# STM32WBA50xx register map
File version: 1.0
Registers are 32-bit, read-write, reset 0x0 unless marked. A register's access mark holds for its fields unless they carry their own. Offsets are from the block's base; [hi:lo] are bit positions; {n}, {i} and the like mark numbered series; 'fields as' and 'values as' point back to an identical list.

## PKA
Base 0x420C2000
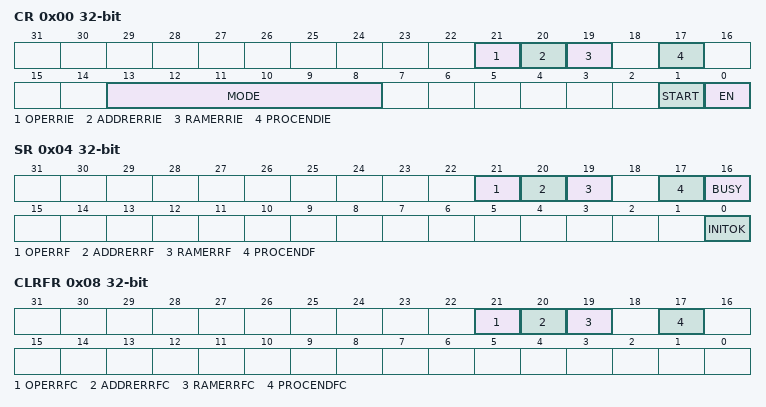
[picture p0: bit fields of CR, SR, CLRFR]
0x00 CR — PKA control register
  [21] OPERRIE — Operation Error interrupt enable
  [20] ADDRERRIE — Address error interrupt enable
  [19] RAMERRIE — RAM error interrupt enable
  [17] PROCENDIE — End of operation interrupt enable
  [13:8] MODE — MODE[5:0] PKA operation code
  [1] START — Start operation
  [0] EN — PKA enable
0x04 SR — PKA status register
  [21] OPERRF — PKA operation Error flag
  [20] ADDRERRF — Address error flag
  [19] RAMERRF — PKA RAM error flag
  [17] PROCENDF — PKA end of operation flag
  [16] BUSY — PKA operation is in progress
  [0] INITOK — PKA initialisation flag
0x08 CLRFR — PKA clear flag register
  [21] OPERRFC — Clear PKA operation Error flag
  [20] ADDRERRFC — Clear address error flag
  [19] RAMERRFC — Clear PKA RAM error flag
  [17] PROCENDFC — Clear PKA end of operation flag
{0x400+4i} RAM[{i}] (i=0..1333)

## SYSCFG — System configuration controller
Base 0x46000400
0x00 SECCFGR — SYSCFG secure configuration register
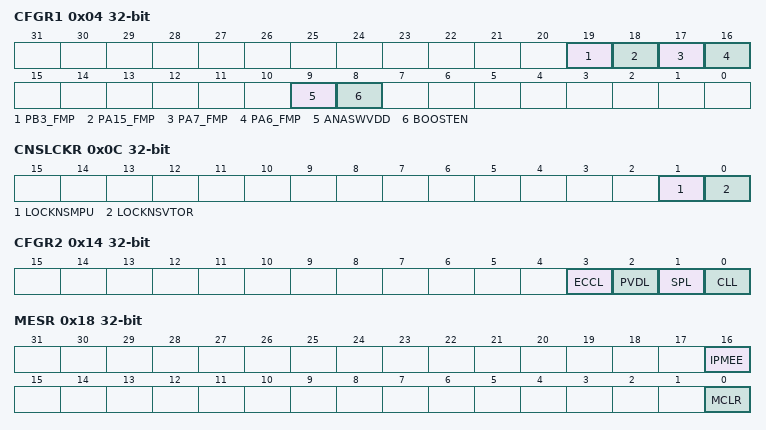
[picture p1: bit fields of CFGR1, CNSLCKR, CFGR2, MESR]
0x04 CFGR1 — SYSCFG configuration register 1
  [19] PB3_FMP — I2C PB3 Fast mode plus
  [18] PA15_FMP — I2C PA15 Fast mode plus
  [17] PA7_FMP — I2C PA7 Fast mode plus
  [16] PA6_FMP — I2C PA6 Fast mode plus
  [9] ANASWVDD — GPIO analog switch control voltage selection
  [8] BOOSTEN — I/O analog switch voltage booster enable
0x08 FPUIMR — SYSCFG FPU interrupt mask register
  [5:0] FPU_IE — All FPU interrupts enable
0x0C CNSLCKR — SYSCFG CPU non-secure lock register
  [1] LOCKNSMPU — Disable Non-Secure MPU registers writes by SW or debug agent
  [0] LOCKNSVTOR — Disable VTOR_NS register writes by SW or debug agent
0x10 CSLCKR — SYSCFG CPU secure lock register
0x14 CFGR2 — SYSCFG configuration register 2
  [3] ECCL — ECC Lock
  [2] PVDL — PVD Lock
  [1] SPL — SRAM Parity Lock
  [0] CLL — Core Lockup Lock
0x18 MESR — SYSCFG Memory Erase Status register
  [16] IPMEE — Status of End of Erase for ICache and PKA RAMs
  [0] MCLR — Status of Erase after Reset
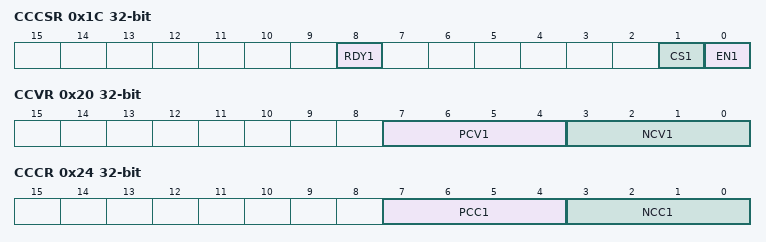
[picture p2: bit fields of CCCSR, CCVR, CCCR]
0x1C CCCSR — SYSCFG Conpensation Cell Control&Status register
  [8] RDY1 — VDD compensation cell ready flag
  [1] CS1 — Code selection for VDD power rail
  [0] EN1 — Enable compensation cell for VDD power rail
0x20 CCVR — SYSCFG Conpensation Cell value register
  [7:4] PCV1 — PMOS compensation value for VDD Power Rail
  [3:0] NCV1 — NMOS compensation value for VDD Power Rail
0x24 CCCR — SYSCFG Conpensation Cell Code register
  [7:4] PCC1 — PMOS compensation code for VDD Power Rail
  [3:0] NCC1 — NMOS compensation code for VDD Power Rail
0x2C RSSCMDR — SYSCFG RSS command mode register

## RTC — Real-Time Clock
Base 0x46007800
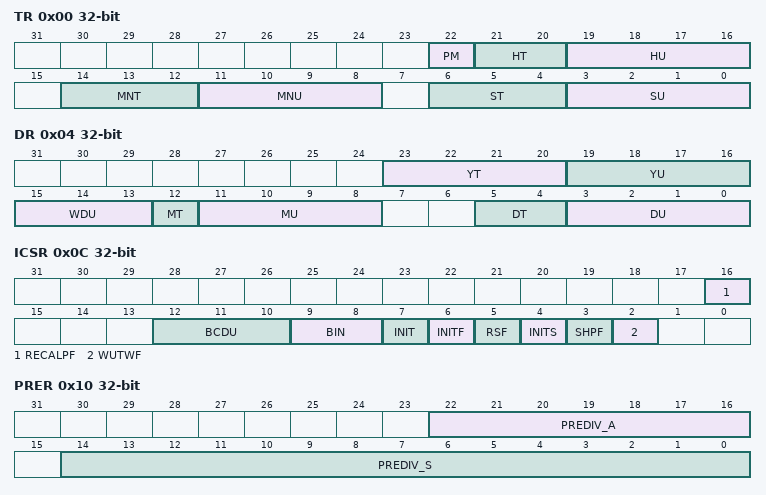
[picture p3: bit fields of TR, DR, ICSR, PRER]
0x00 TR — RTC time register
  [22] PM
    0=AM_OR_24 (AM or 24-hour format); 1=PM
  [21:20] HT
  [19:16] HU
  [14:12] MNT
  [11:8] MNU
  [6:4] ST
  [3:0] SU
0x04 DR — RTC date register
  [23:20] YT, [19:16] YU, [15:13] WDU, [12] MT, [11:8] MU, [5:4] DT, [3:0] DU
0x08 SSR — RTC sub second register
  [31:0] SS
0x0C ICSR — RTC initialization control and status register
  [16] RECALPF
  [12:10] BCDU
    {v}=1s calendar increment is generated each time SS[{v+7}:0] = 0 (v=0..7)
  [9:8] BIN
    0=NONE (Free running BCD calendar mode (Binary mode disabled)); 1=ONLY (Free running Binary mode (BCD mode disabled)); 2=MIX (Free running BCD calendar and Binary mode enable)
  [7] INIT
  [6] INITF
  [5] RSF
  [4] INITS
  [3] SHPF
  [2] WUTWF
0x10 PRER — RTC prescaler register
  [22:16] PREDIV_A, [14:0] PREDIV_S
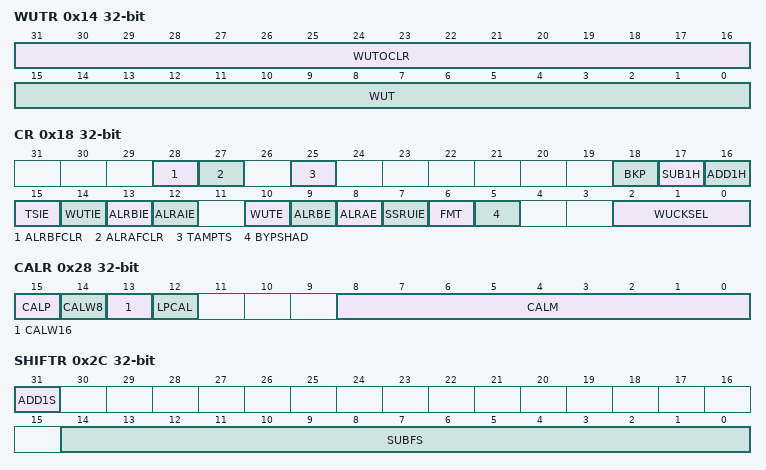
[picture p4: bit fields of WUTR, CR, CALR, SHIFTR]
0x14 WUTR — RTC wakeup timer register
  [31:16] WUTOCLR, [15:0] WUT
0x18 CR — RTC control register
  [28] ALRBFCLR — Alarm B mask
  [27] ALRAFCLR — Alarm A mask
  [25] TAMPTS — Activate timestamp on tamper detection event
  [18] BKP
  [17] SUB1H
  [16] ADD1H
  [15] TSIE
  [14] WUTIE
  [13] ALRBIE
  [12] ALRAIE
  [10] WUTE
  [9] ALRBE
  [8] ALRAE
  [7] SSRUIE
  [6] FMT
    0=HOURFORMAT_24HOUR (24 hour/day format); 1=AMPM (AM/PM hour format)
  [5] BYPSHAD
  [2:0] WUCKSEL
    0=DIV_16 (RTC/16 clock is selected); 1=DIV_8 (RTC/8 clock is selected); 2=DIV_4 (RTC/4 clock is selected); 3=DIV_2 (RTC/2 clock is selected); 4=CKSPRE (ck_spre (usually 1 Hz) clock is selected); 6=CKSPRE_WUT (ck_spre (usually 1 Hz) clock is selected and 2exp16 is added to the WUT counter value)
0x24 WPR — RTC write protection register
  [7:0] KEY
0x28 CALR — RTC calibration register
  [15] CALP
    0=NONE (No RTCCLK pulses are added); 1=SET (One RTCCLK pulse is effectively inserted every 2exp11 pulses (frequency increased by 488.5 ppm))
  [14] CALW8
  [13] CALW16
  [12] LPCAL
  [8:0] CALM
0x2C SHIFTR — RTC shift control register
  [31] ADD1S, [14:0] SUBFS
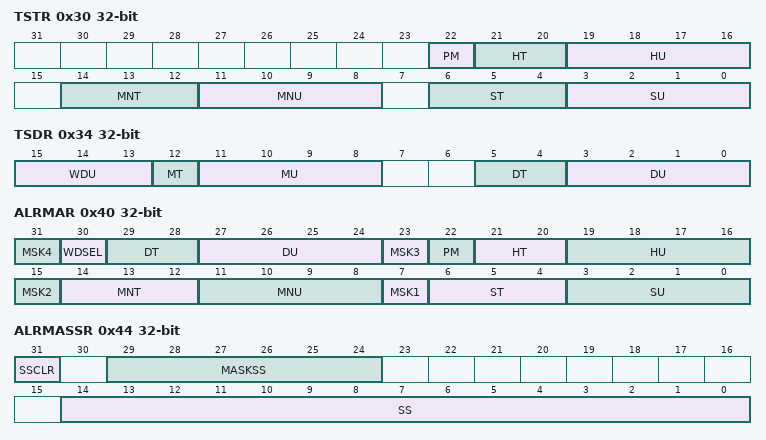
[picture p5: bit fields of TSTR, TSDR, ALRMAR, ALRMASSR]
0x30 TSTR — RTC time stamp time register
  [22] PM
    0=AM (AM or 24-hour format); 1=PM
  [21:20] HT
  [19:16] HU
  [14:12] MNT
  [11:8] MNU
  [6:4] ST
  [3:0] SU
0x34 TSDR — RTC time stamp date register
  [15:13] WDU, [12] MT, [11:8] MU, [5:4] DT, [3:0] DU
0x38 TSSSR — RTC time-stamp sub second register
  [31:0] SS — rtc timestamp sub second >
0x40 ALRMAR — RTC alarm A register
  [8n-1] MSK{n} (n=1..4)
  [30] WDSEL
  [29:28] DT
  [27:24] DU
  [22] PM
    0=AM (AM or 24-hour format); 1=PM
  [21:20] HT
  [19:16] HU
  [14:12] MNT
  [11:8] MNU
  [6:4] ST
  [3:0] SU
0x44 ALRMASSR — RTC alarm A sub second register
  [31] SSCLR
    0=NO; 1=YES
  [29:24] MASKSS
  [14:0] SS
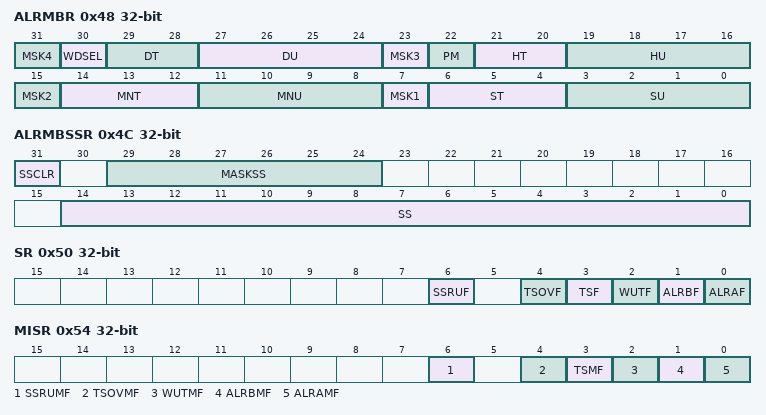
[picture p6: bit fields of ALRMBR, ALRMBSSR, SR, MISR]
0x48 ALRMBR — RTC alarm B register
  fields as ALRMAR
0x4C ALRMBSSR — RTC alarm B sub second register
  [31] SSCLR
    0=NO; 1=YES
  [29:24] MASKSS
  [14:0] SS
0x50 SR — RTC Status register
  [6] SSRUF, [4] TSOVF, [3] TSF, [2] WUTF, [1] ALRBF, [0] ALRAF
0x54 MISR — RTC masked interrupt status register
  [6] SSRUMF, [4] TSOVMF, [3] TSMF, [2] WUTMF, [1] ALRBMF, [0] ALRAMF
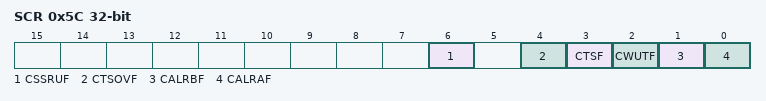
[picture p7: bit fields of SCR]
0x5C SCR — RTC status Clear register
  [6] CSSRUF, [4] CTSOVF, [3] CTSF, [2] CWUTF, [1] CALRBF, [0] CALRAF
0x70 ALRABINR — RTC alarm A binary mode register
  [31:0] SS
0x74 ALRBBINR — RTC alarm B binary mode register
  [31:0] SS
